# CY8C3246PVI_147 register map
File version: 0.1
Registers are 8-bit, read-write, no defined reset value unless marked. A register's access mark holds for its fields unless they carry their own. Offsets are from the block's base; [hi:lo] are bit positions; 'fields as' and 'values as' point back to an identical list.

## WATCHDOG_ENABLER
Base 0x00000000
0x6479 WATCHDOG_ENABLER_CONTROL_REG

## ADC_STATUS
Base 0x00000000
0x656A ADC_STATUS_STATUS_REG
0x658A ADC_STATUS_MASK_REG
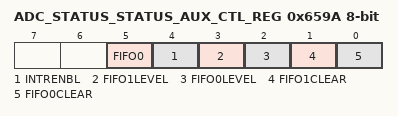
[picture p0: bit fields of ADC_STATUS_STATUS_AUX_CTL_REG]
0x659A ADC_STATUS_STATUS_AUX_CTL_REG
  [5] FIFO0 — FIFO0 clear
    1=ENABLED (Enable counter); 0=DISABLED (Disable counter)
  [4] INTRENBL — Enables or disables the Interrupt
    1=ENABLED (Interrupt enabled); 0=DISABLED (Interrupt disabled)
  [3] FIFO1LEVEL — FIFO level
    1=ENABLED (FIFO LVL: input mode: FIFO at least 1/2 empty; output mode: FIFO at least 1/2 full); 0=DISABLED (FIFO LVL: input mode: FIFO not full; output mode: FIFO not empty)
  [2] FIFO0LEVEL — FIFO level
    values as FIFO1LEVEL
  [1] FIFO1CLEAR — FIFO clear
    1=ENABLED (Clear FIFO state); 0=DISABLED (Normal FIFO operation)
  [0] FIFO0CLEAR — FIFO clear
    values as FIFO1CLEAR

## MOTOR_DIR
Base 0x00000000
0x6478 MOTOR_DIR_CONTROL_REG

## ADC_SOC
Base 0x00000000
0x6575 ADC_SOC_CONTROL_REG

## COUNTER_ENC
Base 0x00000000
0x640B COUNTER_ENC_COUNTER — UDB.A0 - Current Counter Value
0x642B COUNTER_ENC_PERIOD — UDB.D0 - Assigned Period
0x643B COUNTER_ENC_COMPARE — UDB.D1 - Assigned Compare Value
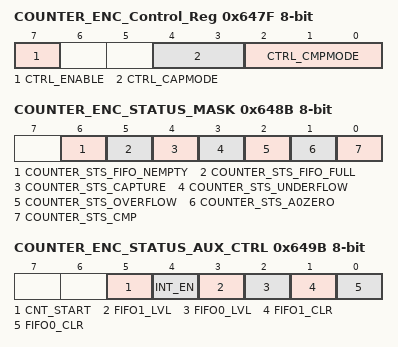
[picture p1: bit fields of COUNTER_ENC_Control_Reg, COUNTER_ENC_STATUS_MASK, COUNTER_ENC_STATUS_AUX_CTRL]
0x647F COUNTER_ENC_Control_Reg — UDB Control Register - Assigned Control Register Value
  [7] CTRL_ENABLE — Enable Counter
  [4:3] CTRL_CAPMODE — Capture mode
  [2:0] CTRL_CMPMODE — Compare mode
0x648B COUNTER_ENC_STATUS_MASK — UDB Status bits Interrupt Mask Enable Register
  [6] COUNTER_STS_FIFO_NEMPTY — FIFO Not Empty Status
  [5] COUNTER_STS_FIFO_FULL — FIFO Full Status
  [4] COUNTER_STS_CAPTURE — Capture Status
  [3] COUNTER_STS_UNDERFLOW — Underflow status
  [2] COUNTER_STS_OVERFLOW — Overflow status
  [1] COUNTER_STS_A0ZERO — A0 Zero ouput status
  [0] COUNTER_STS_CMP — Compare output status
0x649B COUNTER_ENC_STATUS_AUX_CTRL — UDB Auxilliary Control Register
  [5] CNT_START — FIFO0 clear
    0=E_CNT_START0 (Disable counter); 1=E_CNT_START1 (Enable counter)
  [4] INT_EN
    0=E_INT_EN0 (Interrupt disabled); 1=E_INT_EN1 (Interrupt enabled)
  [3] FIFO1_LVL — FIFO level
    0=E_FIFO_LVL_0 (FIFO LVL: input mode: FIFO not full; output mode: FIFO not empty); 1=E_FIFO_LVL_1 (FIFO LVL: input mode: FIFO at least 1/2 empty; output mode: FIFO at least 1/2 full)
  [2] FIFO0_LVL — FIFO level
    values as FIFO1_LVL
  [1] FIFO1_CLR — FIFO1 clear
    0=E_FIFO_CLR_0 (Normal FIFO operation); 1=E_FIFO_CLR_1 (Clear FIFO state)
  [0] FIFO0_CLR — FIFO0 clear
    values as FIFO1_CLR

## UART_RS485 — UART
Base 0x00000000
0x6422 RX_UART_RS485_RX_ADDRESS1 — RX Address1 Register
0x6432 RX_UART_RS485_RX_ADDRESS2 — RX Address2 Register
0x6440 TX_UART_RS485_TX_DATA — TX Data Register
0x6442 RX_UART_RS485_RX_DATA — RX Data Register
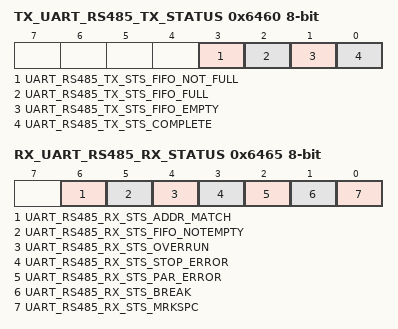
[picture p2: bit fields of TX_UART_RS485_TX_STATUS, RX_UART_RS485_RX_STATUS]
0x6460 TX_UART_RS485_TX_STATUS — TX status register
  [3] UART_RS485_TX_STS_FIFO_NOT_FULL ro, [2] UART_RS485_TX_STS_FIFO_FULL ro, [1] UART_RS485_TX_STS_FIFO_EMPTY ro, [0] UART_RS485_TX_STS_COMPLETE ro
0x6465 RX_UART_RS485_RX_STATUS — RX status register
  [6] UART_RS485_RX_STS_ADDR_MATCH ro, [5] UART_RS485_RX_STS_FIFO_NOTEMPTY ro, [4] UART_RS485_RX_STS_OVERRUN ro, [3] UART_RS485_RX_STS_STOP_ERROR ro, [2] UART_RS485_RX_STS_PAR_ERROR ro, [1] UART_RS485_RX_STS_BREAK ro, [0] UART_RS485_RX_STS_MRKSPC ro

## PWM_MOTORS
Base 0x00000000
0x6427 PWM_MOTORS__COMPARE1 — UDB.D0 - Assigned Compare1 Value
0x6437 PWM_MOTORS__COMPARE2 — UDB.D1 - Assigned Compare2 Value
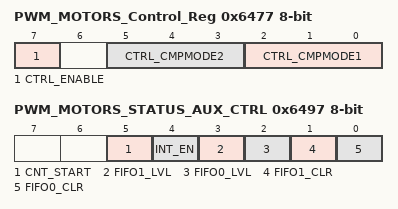
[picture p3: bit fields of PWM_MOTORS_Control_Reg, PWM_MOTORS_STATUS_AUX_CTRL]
0x6477 PWM_MOTORS_Control_Reg — UDB Control Register - Assigned Control Register Value
  [7] CTRL_ENABLE — Enable the PWM
  [5:3] CTRL_CMPMODE2 — Compare mode 2
  [2:0] CTRL_CMPMODE1 — Compare mode 1
0x6497 PWM_MOTORS_STATUS_AUX_CTRL — UDB Auxilliary Control Register
  [5] CNT_START — FIFO0 clear
    0=E_CNT_START0 (Disable counter); 1=E_CNT_START1 (Enable counter)
  [4] INT_EN
    0=E_INT_EN0 (Interrupt disabled); 1=E_INT_EN1 (Interrupt enabled)
  [3] FIFO1_LVL — FIFO level
    0=E_FIFO_LVL_0 (FIFO LVL: input mode: FIFO not full; output mode: FIFO not empty); 1=E_FIFO_LVL_1 (FIFO LVL: input mode: FIFO at least 1/2 empty; output mode: FIFO at least 1/2 full)
  [2] FIFO0_LVL — FIFO level
    values as FIFO1_LVL
  [1] FIFO1_CLR — FIFO1 clear
    0=E_FIFO_CLR_0 (Normal FIFO operation); 1=E_FIFO_CLR_1 (Clear FIFO state)
  [0] FIFO0_CLR — FIFO0 clear
    values as FIFO1_CLR
